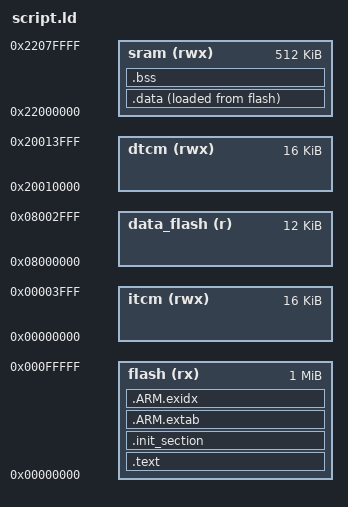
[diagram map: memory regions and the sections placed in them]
/****************************************************************************
 * boards/renesas/fpb-ra8e1/nuttx-config/scripts/script.ld
 *
 * Licensed to the Apache Software Foundation (ASF) under one or more
 * contributor license agreements.  See the NOTICE file distributed with
 * this work for additional information regarding copyright ownership.  The
 * ASF licenses this file to you under the Apache License, Version 2.0 (the
 * "License"); you may not use this file except in compliance with the
 * License.  You may obtain a copy of the License at
 *
 *   http://www.apache.org/licenses/LICENSE-2.0
 *
 * Unless required by applicable law or agreed to in writing, software
 * distributed under the License is distributed on an "AS IS" BASIS, WITHOUT
 * WARRANTIES OR CONDITIONS OF ANY KIND, either express or implied.  See the
 * License for the specific language governing permissions and limitations
 * under the License.
 *
 ****************************************************************************/

/* The Renesas RA8E1 (R7FA8E1AFDCFB) has:
 * - 1MB of FLASH beginning at address 0x0000:0000
 * - 512KB of SRAM beginning at address 0x2200:0000
 * - 16KB of ITCM beginning at address 0x0000:0000 (overlays flash)
 * - 16KB of DTCM beginning at address 0x2001:0000
 * - 12KB of Data Flash beginning at address 0x0800:0000
 */

MEMORY
{
    flash (rx)   : ORIGIN = 0x00000000, LENGTH = 1024K
    sram (rwx)   : ORIGIN = 0x22000000, LENGTH = 512K
    itcm (rwx)   : ORIGIN = 0x00000000, LENGTH = 16K
    dtcm (rwx)   : ORIGIN = 0x20010000, LENGTH = 16K
    data_flash (r) : ORIGIN = 0x08000000, LENGTH = 12K
}

OUTPUT_ARCH(arm)
ENTRY(_stext)
SECTIONS
{
    .text : {
        _stext = ABSOLUTE(.);
        *(.vectors)
        *(.text .text.*)
        *(.fixup)
        *(.gnu.warning)
        *(.rodata .rodata.*)
        *(.gnu.linkonce.t.*)
        *(.glue_7)
        *(.glue_7t)
        *(.got)
        *(.gcc_except_table)
        *(.gnu.linkonce.r.*)
        _etext = ABSOLUTE(.);
    } > flash

    .init_section : {
        _sinit = ABSOLUTE(.);
        *(.init_array .init_array.*)
        _einit = ABSOLUTE(.);
    } > flash

    .ARM.extab : {
        *(.ARM.extab*)
    } > flash

    .ARM.exidx : {
        __exidx_start = ABSOLUTE(.);
        *(.ARM.exidx*)
        __exidx_end = ABSOLUTE(.);
    } > flash

    .data : {
        _sdata = ABSOLUTE(.);
        *(.data .data.*)
        *(.gnu.linkonce.d.*)
        CONSTRUCTORS
        . = ALIGN(4);
        _edata = ABSOLUTE(.);
    } > sram AT > flash

    _eronly = LOADADDR(.data);

    .bss : {
        _sbss = ABSOLUTE(.);
        *(.bss .bss.*)
        *(.gnu.linkonce.b.*)
        *(COMMON)
        . = ALIGN(4);
        _ebss = ABSOLUTE(.);
    } > sram

    /* Stabs debugging sections. */
    .stab 0 : { *(.stab) }
    .stabstr 0 : { *(.stabstr) }
    .stab.excl 0 : { *(.stab.excl) }
    .stab.exclstr 0 : { *(.stab.exclstr) }
    .stab.index 0 : { *(.stab.index) }
    .stab.indexstr 0 : { *(.stab.indexstr) }
    .comment 0 : { *(.comment) }
    .debug_abbrev 0 : { *(.debug_abbrev) }
    .debug_info 0 : { *(.debug_info) }
    .debug_line 0 : { *(.debug_line) }
    .debug_pubnames 0 : { *(.debug_pubnames) }
    .debug_aranges 0 : { *(.debug_aranges) }
}
